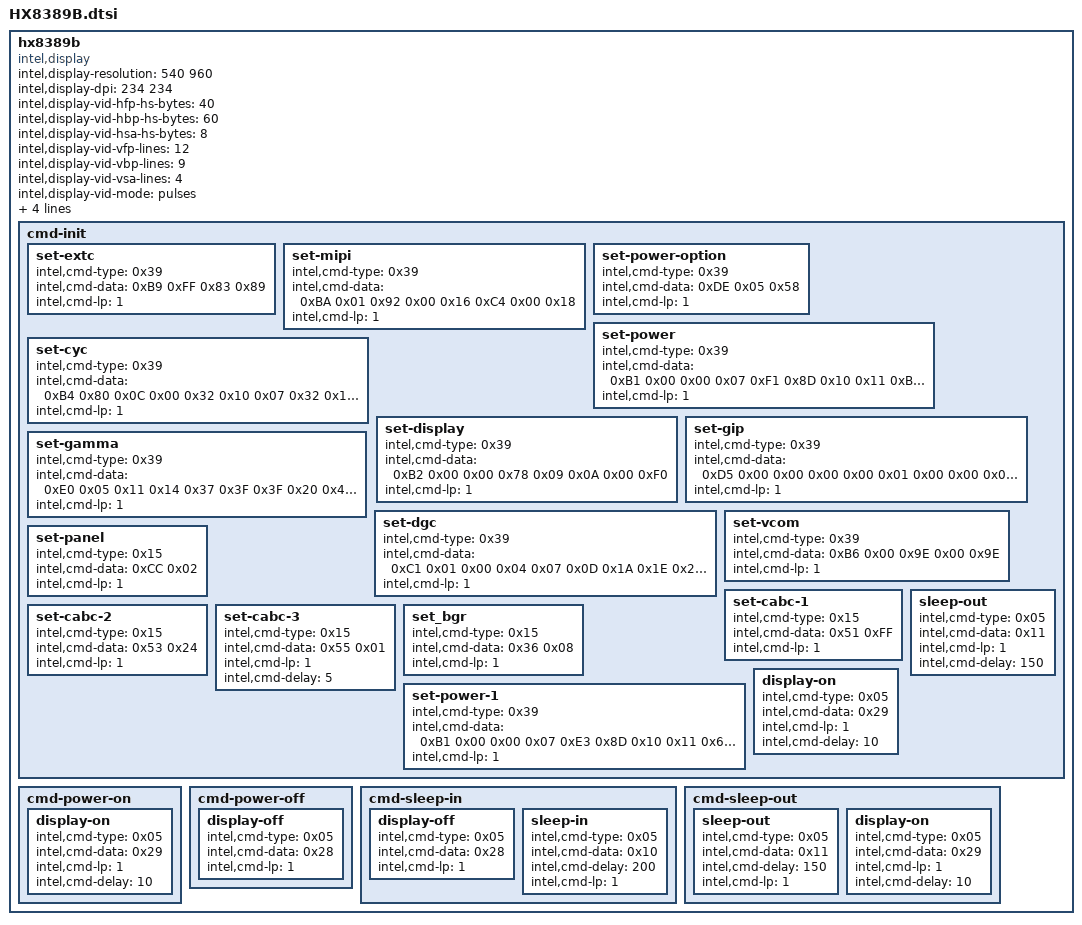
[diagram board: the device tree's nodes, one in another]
	hx8389b {
		compatible = "intel,display";
		intel,display-resolution= <540 960>;
		intel,display-dpi= <234 234>;

		/* MIPI-DSI video mode settings */
		intel,display-vid-hfp-hs-bytes = <40>;
		intel,display-vid-hbp-hs-bytes = <60>;
		intel,display-vid-hsa-hs-bytes = <8>;
		intel,display-vid-vfp-lines = <12>;
		intel,display-vid-vbp-lines = <9>;
		intel,display-vid-vsa-lines = <4>;

		intel,display-vid-mode = "pulses";
		intel,display-vid-id = <0>;
		intel,display-vid-pixel = "24packed";
		intel,display-vid-fill_buf_to = <0x1F>;

		intel,display-reset = <1 1 0 2 1 10>;

		cmd-init {
			set-extc {
				intel,cmd-type = <0x39>;
				intel,cmd-data = <0xB9 0xFF 0x83 0x89>;
				intel,cmd-lp = <1>;
			};
			set-mipi {
				intel,cmd-type = <0x39>;
				intel,cmd-data = <0xBA 0x01 0x92 0x00 0x16 0xC4 0x00 0x18>;
				intel,cmd-lp = <1>;
			};
			set-power-option {
				intel,cmd-type = <0x39>;
				intel,cmd-data = <0xDE 0x05 0x58>;
				intel,cmd-lp = <1>;
			};
			set-power {
				intel,cmd-type = <0x39>;
				intel,cmd-data = <0xB1 0x00 0x00 0x07 0xF1 0x8D 0x10 0x11 0xB2 0x0C 0x1D 0x25 0x1E 0x1E 0x41 0x01 0x58 0xF7 0x00 0xC0>;
				intel,cmd-lp = <1>;
			};
			set-cyc {
				intel,cmd-type = <0x39>;
				intel,cmd-data = <0xB4 0x80 0x0C 0x00 0x32 0x10 0x07 0x32 0x10 0x00 0x00 0x00 0x00 0x17 0x0A 0x40 0x0B 0x13 0x00 0x4B 0x14 0x53 0x53 0x0A>;
				intel,cmd-lp = <1>;
			};
			set-display {
				intel,cmd-type = <0x39>;
				intel,cmd-data = <0xB2 0x00 0x00 0x78 0x09 0x0A 0x00 0xF0>;
				intel,cmd-lp = <1>;
			};
			set-gip {
				intel,cmd-type = <0x39>;
				intel,cmd-data = <0xD5 0x00 0x00 0x00 0x00 0x01 0x00 0x00 0x00 0x20 0x00 0x99 0x88 0x88 0x88 0x88 0x88 0x88 0x88 0x88 0x23 0x88 0x01 0x01 0x88 0x88 0x88 0x88 0x88 0x88 0x88 0x99 0x88 0x88 0x88 0x88 0x88 0x88 0x88 0x10 0x88 0x32 0x10 0x88 0x88 0x88 0x88 0x88 0x88>;
				intel,cmd-lp = <1>;
			};
			set-gamma {
				intel,cmd-type = <0x39>;
				intel,cmd-data = <0xE0 0x05 0x11 0x14 0x37 0x3F 0x3F 0x20 0x4F 0x08 0x0E 0x0D 0x12 0x14 0x12 0x14 0x1D 0x1C 0x05 0x11 0x14 0x37 0x3F 0x3F 0x20 0x4F 0x08 0x0E 0x0D 0x12 0x14 0x12 0x14 0x1D 0x1C>;
				intel,cmd-lp = <1>;
			};
			set-dgc {
				intel,cmd-type = <0x39>;
				intel,cmd-data = <0xC1 0x01 0x00 0x04 0x07 0x0D 0x1A 0x1E 0x25 0x2C 0x35 0x3D 0x46 0x4F 0x58 0x60 0x6A 0x74 0x7D 0x85 0x8E 0x98 0xA0 0xAA 0xB2 0xBF 0xC8 0xCB 0xD4 0xE0 0xE5 0xF1 0xF5 0xFB 0xFF 0x80 0x2F 0x37 0x2F 0x35 0x91 0x24 0x6A 0xC0 0x00 0x04 0x07 0x0D 0x1A 0x1E 0x25 0x2C 0x35 0x3D 0x46 0x4F 0x58 0x60 0x6A 0x74 0x7D 0x85 0x8E 0x98 0xA0 0xAA 0xB2 0xBF 0xC8 0xCB 0xD4 0xE0 0xE5 0xF1 0xF5 0xFB 0xFF 0x80 0x2F 0x37 0x2F 0x35 0x91 0x24 0x6A 0xC0 0x00 0x04 0x07 0x0D 0x19 0x1D 0x25 0x2C 0x35 0x3D 0x46 0x4F 0x58 0x60 0x6A 0x74 0x7D 0x85 0x8E 0x98 0xA0 0xAA 0xB2 0xBF 0xC8 0xCB 0xD4 0xE0 0xE5 0xF1 0xF5 0xFB 0xFF 0x80 0x2F 0x37 0x2F 0x35 0x91 0x24 0x6A 0xC0>;
				intel,cmd-lp = <1>;
			};
			set-vcom {
				intel,cmd-type = <0x39>;
				intel,cmd-data = <0xB6 0x00 0x9E 0x00 0x9E>;
				intel,cmd-lp = <1>;
			};
			set-panel {
				intel,cmd-type = <0x15>;
				intel,cmd-data = <0xCC 0x02>;
				intel,cmd-lp = <1>;
			};
			set-cabc-1 {
				intel,cmd-type = <0x15>;
				intel,cmd-data = <0x51 0xFF>;
				intel,cmd-lp = <1>;
			};
			set-cabc-2 {
				intel,cmd-type = <0x15>;
				intel,cmd-data = <0x53 0x24>;
				intel,cmd-lp = <1>;
			};
			set-cabc-3 {
				intel,cmd-type = <0x15>;
				intel,cmd-data = <0x55 0x01>;
				intel,cmd-lp = <1>;
				intel,cmd-delay = <5>;
			};
			set_bgr {
				intel,cmd-type = <0x15>;
				intel,cmd-data = <0x36 0x08>;
				intel,cmd-lp = <1>;
			};
			sleep-out {
				intel,cmd-type = <0x05>;
				intel,cmd-data = <0x11>;
				intel,cmd-lp = <1>;
				intel,cmd-delay = <150>;
			};
			set-power-1 {
				intel,cmd-type = <0x39>;
				intel,cmd-data = <0xB1 0x00 0x00 0x07 0xE3 0x8D 0x10 0x11 0x6F 0x0C 0x1D 0x25 0x1E 0x1E 0x41 0x01 0x58 0xF7 0x00 0x00>;
				intel,cmd-lp = <1>;
			};
			display-on {
				intel,cmd-type = <0x05>;
				intel,cmd-data = <0x29>;
				intel,cmd-lp = <1>;
				intel,cmd-delay = <10>;
			};
		};

		cmd-power-on {
			display-on {
				intel,cmd-type = <0x05>;
				intel,cmd-data = <0x29>;
				intel,cmd-lp = <1>;
				intel,cmd-delay = <10>;
			};
		};

		cmd-power-off {
			display-off {
				intel,cmd-type = <0x05>;
				intel,cmd-data = <0x28>;
				intel,cmd-lp = <1>;
			};
		};

		cmd-sleep-in {
			display-off {
				intel,cmd-type = <0x05>;
				intel,cmd-data = <0x28>;
				intel,cmd-lp = <1>;
			};
			sleep-in {
				intel,cmd-type = <0x05>;
				intel,cmd-data = <0x10>;
				intel,cmd-delay = <200>;
				intel,cmd-lp = <1>;
			};
		};

		cmd-sleep-out {
			sleep-out {
				intel,cmd-type = <0x05>;
				intel,cmd-data = <0x11>;
				intel,cmd-delay = <150>;
				intel,cmd-lp = <1>;
			};
			display-on {
				intel,cmd-type = <0x05>;
				intel,cmd-data = <0x29>;
				intel,cmd-lp = <1>;
				intel,cmd-delay = <10>;
			};
		};

	};
